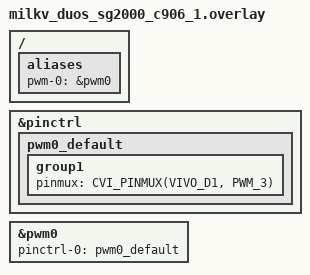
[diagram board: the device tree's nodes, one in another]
/*
 * Copyright (c) 2024 Chen Xingyu <hi@xingrz.me>
 * SPDX-License-Identifier: Apache-2.0
 */

/ {
	aliases {
		pwm-0 = &pwm0;
	};
};

&pinctrl {
	pwm0_default: pwm0_default {
		group1 {
			pinmux = <CVI_PINMUX(VIVO_D1, PWM_3)>;  /* B20 */
		};
	};
};

&pwm0 {
	status = "okay";
	pinctrl-0 = <&pwm0_default>;
	pinctrl-names = "default";
};
